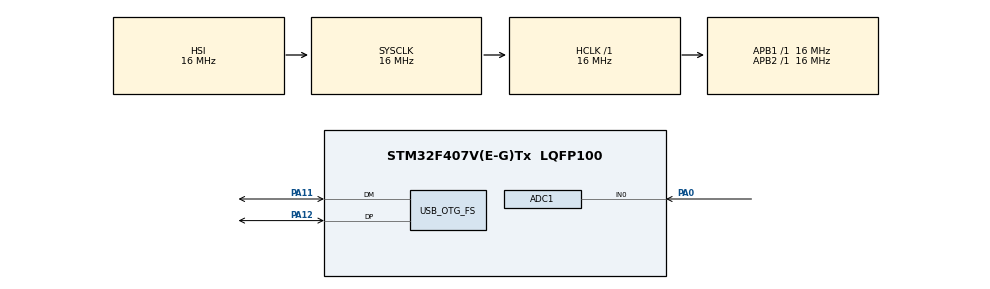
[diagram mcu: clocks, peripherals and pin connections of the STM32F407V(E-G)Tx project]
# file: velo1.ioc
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ADC1.Channel-0\#ChannelRegularConversion=ADC_CHANNEL_0
ADC1.NbrOfConversionFlag=1
ADC1.Rank-0\#ChannelRegularConversion=1
ADC1.SamplingTime-0\#ChannelRegularConversion=ADC_SAMPLETIME_480CYCLES
ADC1.master=1
EdgeImpulse.myFinalproject.1.0.4.MachineLearningCcmyFinalprojectJjCore=true
Mcu.Family=STM32F4
Mcu.Name=STM32F407V(E-G)Tx
Mcu.Package=LQFP100
NVIC.OTG_FS_IRQn=true\:0\:0\:false\:false\:true\:false\:true\:true
NVIC.PriorityGroup=NVIC_PRIORITYGROUP_4
PA0-WKUP.Signal=ADCx_IN0
PA11.Mode=Device_Only
PA11.Signal=USB_OTG_FS_DM
PA12.Mode=Device_Only
PA12.Signal=USB_OTG_FS_DP
PA13.Mode=Trace_Asynchronous_SW
PA13.Signal=SYS_JTMS-SWDIO
PA14.Mode=Trace_Asynchronous_SW
PA14.Signal=SYS_JTCK-SWCLK
PB3.Mode=Trace_Asynchronous_SW
PB3.Signal=SYS_JTDO-SWO
PH0-OSC_IN.Mode=HSE-External-Oscillator
PH0-OSC_IN.Signal=RCC_OSC_IN
PH1-OSC_OUT.Mode=HSE-External-Oscillator
PH1-OSC_OUT.Signal=RCC_OSC_OUT
ProjectManager.HeapSize=0x200
ProjectManager.StackSize=0x400
ProjectManager.TargetToolchain=STM32CubeIDE
RCC.48MHZClocksFreq_Value=48000000
RCC.AHBFreq_Value=16000000
RCC.APB1Freq_Value=16000000
RCC.APB2Freq_Value=16000000
RCC.CortexFreq_Value=16000000
RCC.HSE_VALUE=8000000
RCC.HSI_VALUE=16000000
RCC.LSE_VALUE=32768
RCC.PLLM=4
RCC.PLLN=72
RCC.PLLQ=3
RCC.SYSCLKFreq_VALUE=16000000
RCC.VCOOutputFreq_Value=144000000
SH.ADCx_IN0.0=ADC1_IN0,IN0
USB_DEVICE.CLASS_NAME_FS=CDC
USB_DEVICE.VirtualMode-CDC_FS=Cdc
USB_DEVICE.VirtualModeFS=Cdc_FS
USB_OTG_FS.VirtualMode=Device_Only
VP_CRC_VS_CRC.Mode=CRC_Activate
VP_EdgeImpulse.myFinalproject_VS_myFinalprojectJjMachineLearning_1.0.4_1.0.4.Mode=myFinalprojectJjMachineLearning
VP_USB_DEVICE_VS_USB_DEVICE_CDC_FS.Mode=CDC_FS
board=custom

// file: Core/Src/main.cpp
/* USER CODE BEGIN Header */
/**
  ******************************************************************************
  * @file           : main.c
  * @brief          : Main program body
  ******************************************************************************
  * @attention
  *
  * Copyright (c) 2022 STMicroelectronics.
  * All rights reserved.
  *
  * This software is licensed under terms that can be found in the LICENSE file
  * in the root directory of this software component.
  * If no LICENSE file comes with this software, it is provided AS-IS.
  *
  ******************************************************************************
  */
/* USER CODE END Header */
#include "main.h"
#include "usb_device.h"
#include "usbd_cdc_if.h"
#include "string.h"
#include <stdio.h>

 ADC_HandleTypeDef hadc1;

CRC_HandleTypeDef hcrc;

void SystemClock_Config(void);
static void MX_GPIO_Init(void);
static void MX_ADC1_Init(void);
static void MX_CRC_Init(void);

/* USER CODE BEGIN 0 */
float adc_val;
char *adc_buffer[20];
#include <stdarg.h>
#include "edge-impulse-sdk/classifier/ei_run_classifier.h"
#define DATA_SIZE 1000
 char  recivebuffer[64];
static int64_t sampling_freq = EI_CLASSIFIER_FREQUENCY; // in Hz.
static int64_t time_between_samples_us = (1000000 / (sampling_freq - 1));

static float features[EI_CLASSIFIER_DSP_INPUT_FRAME_SIZE];
float cvalue[300];
using namespace ei;
int get_feature_data(size_t offset, size_t length, float *out_ptr) {
    memcpy(out_ptr, features + offset, length * sizeof(float));
    return 0;
}
void vprint(const char *fmt, va_list argp)
{
    char string[200];
    if(0 < vsprintf(string, fmt, argp)) // build string
    {
        //HAL_UART_Transmit(&huart1, (uint8_t*)string, strlen(string), 0xffffff); // send message via UART
    	CDC_Transmit_FS((uint8_t *) string, strlen(string));
    }
}

void ei_printf(const char *format, ...) {
    va_list myargs;
    va_start(myargs, format);
    vprint(format, myargs);
    va_end(myargs);
}
/* USER CODE END 0 */

int main(void)
{

  /* MCU Configuration--------------------------------------------------------*/

  /* Reset of all peripherals, Initializes the Flash interface and the Systick. */
  HAL_Init();

  /* USER CODE BEGIN Init */
  signal_t signal;
  signal.total_length = sizeof(features) / sizeof(features[0]);
  signal.get_data = &get_feature_data;
  /* USER CODE END Init */

  /* Configure the system clock */
  SystemClock_Config();

  /* Initialize all configured peripherals */
  MX_GPIO_Init();
  MX_ADC1_Init();
  MX_USB_DEVICE_Init();
  MX_CRC_Init();

  /* Infinite loop */
  /* USER CODE BEGIN WHILE */
  while (1)
  {
	  for (size_t ix = 0; ix < EI_CLASSIFIER_DSP_INPUT_FRAME_SIZE; ix += EI_CLASSIFIER_RAW_SAMPLES_PER_FRAME)
	  	  {
		  HAL_ADC_Start(&hadc1);
		 	  	  HAL_ADC_PollForConversion(&hadc1, 100);
		 	  	  adc_val = HAL_ADC_GetValue(&hadc1);
		  features[ix + 0] = adc_val;
		  HAL_ADC_Stop(&hadc1);

	  	  }//for

	  	  ei_impulse_result_t result = { 0 };
	  	       signal_t signal;
	  	       numpy::signal_from_buffer(features, EI_CLASSIFIER_DSP_INPUT_FRAME_SIZE, &signal);
	  	       // run classifier
	  	            EI_IMPULSE_ERROR res = run_classifier(&signal, &result, false);
	  	            ei_printf("run_classifier returned: %d\n", res);
	  	            if (res != 0) return 1;

	  	            // print predictions
	  	            ei_printf("Predictions (DSP: %d ms., Classification: %d ms., Anomaly: %d ms.): \n",
	  	                result.timing.dsp, result.timing.classification, result.timing.anomaly);

	  	            // print the predictions
	  	           for (size_t ix = 0; ix < EI_CLASSIFIER_LABEL_COUNT; ix++) {
	  	                cvalue[ix] = result.classification[ix].value;
	  	          	  ei_printf("%s:\t%f\n", result.classification[ix].label, cvalue[ix]);

	  	            }
	  	         HAL_Delay(1000);
    /* USER CODE END WHILE */

  }
}

void SystemClock_Config(void)
{
  RCC_OscInitTypeDef RCC_OscInitStruct = {0};
  RCC_ClkInitTypeDef RCC_ClkInitStruct = {0};

  /** Configure the main internal regulator output voltage
  */
  __HAL_RCC_PWR_CLK_ENABLE();
  __HAL_PWR_VOLTAGESCALING_CONFIG(PWR_REGULATOR_VOLTAGE_SCALE1);

  /** Initializes the RCC Oscillators according to the specified parameters
  * in the RCC_OscInitTypeDef structure.
  */
  RCC_OscInitStruct.OscillatorType = RCC_OSCILLATORTYPE_HSI|RCC_OSCILLATORTYPE_HSE;
  RCC_OscInitStruct.HSEState = RCC_HSE_ON;
  RCC_OscInitStruct.HSIState = RCC_HSI_ON;
  RCC_OscInitStruct.HSICalibrationValue = RCC_HSICALIBRATION_DEFAULT;
  RCC_OscInitStruct.PLL.PLLState = RCC_PLL_ON;
  RCC_OscInitStruct.PLL.PLLSource = RCC_PLLSOURCE_HSE;
  RCC_OscInitStruct.PLL.PLLM = 4;
  RCC_OscInitStruct.PLL.PLLN = 72;
  RCC_OscInitStruct.PLL.PLLP = RCC_PLLP_DIV2;
  RCC_OscInitStruct.PLL.PLLQ = 3;
  if (HAL_RCC_OscConfig(&RCC_OscInitStruct) != HAL_OK)
  {
    Error_Handler();
  }

  /** Initializes the CPU, AHB and APB buses clocks
  */
  RCC_ClkInitStruct.ClockType = RCC_CLOCKTYPE_HCLK|RCC_CLOCKTYPE_SYSCLK
                              |RCC_CLOCKTYPE_PCLK1|RCC_CLOCKTYPE_PCLK2;
  RCC_ClkInitStruct.SYSCLKSource = RCC_SYSCLKSOURCE_HSI;
  RCC_ClkInitStruct.AHBCLKDivider = RCC_SYSCLK_DIV1;
  RCC_ClkInitStruct.APB1CLKDivider = RCC_HCLK_DIV1;
  RCC_ClkInitStruct.APB2CLKDivider = RCC_HCLK_DIV1;

  if (HAL_RCC_ClockConfig(&RCC_ClkInitStruct, FLASH_LATENCY_0) != HAL_OK)
  {
    Error_Handler();
  }
}

static void MX_ADC1_Init(void)
{

  ADC_ChannelConfTypeDef sConfig = {0};

  /** Configure the global features of the ADC (Clock, Resolution, Data Alignment and number of conversion)
  */
  hadc1.Instance = ADC1;
  hadc1.Init.ClockPrescaler = ADC_CLOCK_SYNC_PCLK_DIV2;
  hadc1.Init.Resolution = ADC_RESOLUTION_12B;
  hadc1.Init.ScanConvMode = DISABLE;
  hadc1.Init.ContinuousConvMode = DISABLE;
  hadc1.Init.DiscontinuousConvMode = DISABLE;
  hadc1.Init.ExternalTrigConvEdge = ADC_EXTERNALTRIGCONVEDGE_NONE;
  hadc1.Init.ExternalTrigConv = ADC_SOFTWARE_START;
  hadc1.Init.DataAlign = ADC_DATAALIGN_RIGHT;
  hadc1.Init.NbrOfConversion = 1;
  hadc1.Init.DMAContinuousRequests = DISABLE;
  hadc1.Init.EOCSelection = ADC_EOC_SINGLE_CONV;
  if (HAL_ADC_Init(&hadc1) != HAL_OK)
  {
    Error_Handler();
  }

  /** Configure for the selected ADC regular channel its corresponding rank in the sequencer and its sample time.
  */
  sConfig.Channel = ADC_CHANNEL_0;
  sConfig.Rank = 1;
  sConfig.SamplingTime = ADC_SAMPLETIME_480CYCLES;
  if (HAL_ADC_ConfigChannel(&hadc1, &sConfig) != HAL_OK)
  {
    Error_Handler();
  }

}

static void MX_CRC_Init(void)
{

  hcrc.Instance = CRC;
  if (HAL_CRC_Init(&hcrc) != HAL_OK)
  {
    Error_Handler();
  }

}

static void MX_GPIO_Init(void)
{

  /* GPIO Ports Clock Enable */
  __HAL_RCC_GPIOH_CLK_ENABLE();
  __HAL_RCC_GPIOA_CLK_ENABLE();
  __HAL_RCC_GPIOB_CLK_ENABLE();

}

void Error_Handler(void)
{
  __disable_irq();
  while (1)
  {
  }
}
